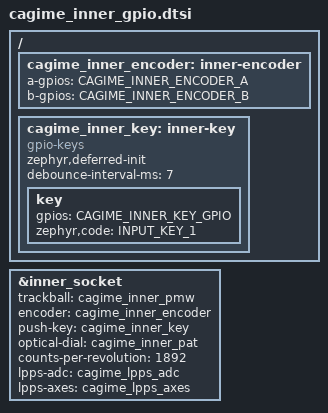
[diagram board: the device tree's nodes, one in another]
/ {
    cagime_inner_encoder: inner-encoder {
        a-gpios = CAGIME_INNER_ENCODER_A;
        b-gpios = CAGIME_INNER_ENCODER_B;
        #include "cagime_encoder.dtsi"
    };

    cagime_inner_key: inner-key {
        compatible = "gpio-keys";
        zephyr,deferred-init;
        debounce-interval-ms = <7>;

        key {
            gpios = CAGIME_INNER_KEY_GPIO;
            zephyr,code = <INPUT_KEY_1>;
        };
    };
};

&inner_socket {
    trackball = <&cagime_inner_pmw>;
    encoder = <&cagime_inner_encoder>;
    push-key = <&cagime_inner_key>;
    optical-dial = <&cagime_inner_pat>;
    counts-per-revolution = <1892>;
    lpps-adc = <&cagime_lpps_adc>;
    lpps-axes = <&cagime_lpps_axes>;
};
